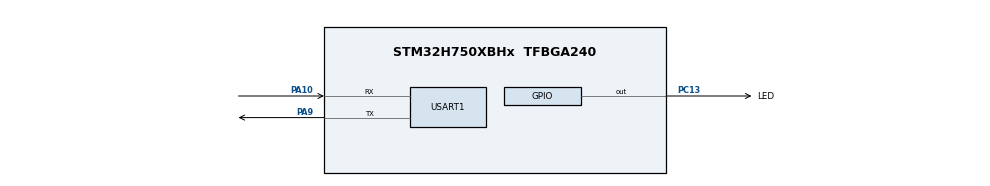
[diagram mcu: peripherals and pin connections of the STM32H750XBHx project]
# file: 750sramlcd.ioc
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CORTEX_M7.CPU_DCache=Enabled
CORTEX_M7.CPU_ICache=Enabled
CORTEX_M7.MPU_Control=__NULL
Mcu.Family=STM32H7
Mcu.Name=STM32H750XBHx
Mcu.Package=TFBGA240
NVIC.PriorityGroup=NVIC_PRIORITYGROUP_4
NVIC.USART1_IRQn=true\:0\:0\:false\:false\:true\:true\:true\:true
PA10.Mode=Asynchronous
PA10.Signal=USART1_RX
PA13\ (JTMS/SWDIO).Mode=Trace_Asynchronous_SW
PA13\ (JTMS/SWDIO).Signal=DEBUG_JTMS-SWDIO
PA14\ (JTCK/SWCLK).Mode=Trace_Asynchronous_SW
PA14\ (JTCK/SWCLK).Signal=DEBUG_JTCK-SWCLK
PA9.Mode=Asynchronous
PA9.Signal=USART1_TX
PB3\ (JTDO/TRACESWO).Mode=Trace_Asynchronous_SW
PB3\ (JTDO/TRACESWO).Signal=DEBUG_JTDO-SWO
PC13.GPIO_Label=LED
PC13.Signal=GPIO_Output
PH0-OSC_IN\ (PH0).Mode=HSE-External-Oscillator
PH0-OSC_IN\ (PH0).Signal=RCC_OSC_IN
PH1-OSC_OUT\ (PH1).Mode=HSE-External-Oscillator
PH1-OSC_OUT\ (PH1).Signal=RCC_OSC_OUT
ProjectManager.HeapSize=0x200
ProjectManager.StackSize=0x400
ProjectManager.TargetToolchain=STM32CubeIDE
RCC.ADCFreq_Value=50390625
RCC.APB1Freq_Value=120000000
RCC.APB2Freq_Value=120000000
RCC.APB3Freq_Value=120000000
RCC.APB4Freq_Value=120000000
RCC.CortexFreq_Value=480000000
RCC.D1PPRE=RCC_APB3_DIV2
RCC.D2PPRE1=RCC_APB1_DIV2
RCC.D2PPRE2=RCC_APB2_DIV2
RCC.D3PPRE=RCC_APB4_DIV2
RCC.DIVM1=5
RCC.DIVM3=5
RCC.DIVN1=192
RCC.DIVQ1=20
RCC.DIVR3=19
RCC.HCLKFreq_Value=240000000
RCC.HPRE=RCC_HCLK_DIV2
RCC.PLL2_VCI_Range-AdvancedSettings=RCC_PLL2VCIRANGE_0
RCC.PLL3FRACN=0
RCC.PLLSourceVirtual=RCC_PLLSOURCE_HSE
RCC.ProductRev=revV
RCC.SYSCLKFreq_VALUE=480000000
RCC.SYSCLKSource=RCC_SYSCLKSOURCE_PLLCLK
RCC.SupplySource=PWR_EXTERNAL_SOURCE_SUPPLY
RCC.USBFreq_Value=48000000
USART1.FIFOMode=FIFOMODE_DISABLE
USART1.Parity=PARITY_EVEN
USART1.VirtualMode-Asynchronous=VM_ASYNC
USART1.WordLength=WORDLENGTH_9B
board=custom

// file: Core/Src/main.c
/* USER CODE BEGIN Header */
/**
  ******************************************************************************
  * @file           : main.c
  * @brief          : Main program body
  ******************************************************************************
  * @attention
  *
  * Copyright (c) 2024 STMicroelectronics.
  * All rights reserved.
  *
  * This software is licensed under terms that can be found in the LICENSE file
  * in the root directory of this software component.
  * If no LICENSE file comes with this software, it is provided AS-IS.
  *
  ******************************************************************************
  */
/* USER CODE END Header */
#include "main.h"

/* USER CODE BEGIN Includes */
#include <stdio.h>

/* USER CODE END Includes */

UART_HandleTypeDef huart1;

void SystemClock_Config(void);
static void MX_GPIO_Init(void);
static void MX_USART1_UART_Init(void);

/* USER CODE BEGIN 0 */

uint8_t recbyte, sendbyte;

void myprintf(char *text){
	HAL_UART_Transmit(&huart1, text, strlen(text),10);
}

int _write(int file, char *ptr, int len)
{
	HAL_UART_Transmit(&huart1, ptr, len,10);
   return len;
}

void HAL_UART_TxCpltCallback(UART_HandleTypeDef *huart)
{
	HAL_GPIO_TogglePin(LED_GPIO_Port,LED_Pin);

}

void HAL_UART_RxCpltCallback(UART_HandleTypeDef *huart){
	sendbyte=recbyte;
	//if((sendbyte>=0x61)&&(sendbyte<=0x7a))sendbyte-=0x20;
	HAL_UART_Transmit(&huart1, &sendbyte,1,10);
	HAL_UART_Receive_IT(&huart1, &recbyte, 1);

	ms_proc_char(recbyte);
}

/* USER CODE END 0 */

int main(void)
{
  /* USER CODE BEGIN 1 */
  // Set stdout to be unbuffered
  //setvbuf(stdout, NULL, _IONBF, 0);

  /* USER CODE END 1 */

  /* Enable I-Cache---------------------------------------------------------*/
  SCB_EnableICache();

  /* Enable D-Cache---------------------------------------------------------*/
  SCB_EnableDCache();

  /* MCU Configuration--------------------------------------------------------*/

  /* Reset of all peripherals, Initializes the Flash interface and the Systick. */
  HAL_Init();

  /* Configure the system clock */
  SystemClock_Config();

  /* Initialize all configured peripherals */
  MX_GPIO_Init();
  MX_USART1_UART_Init();

  /* Infinite loop */
  /* USER CODE BEGIN WHILE */
  printf("Start\n");
  HAL_UART_Receive_IT(&huart1, &recbyte, 1);
  while (1)
  {
    /* USER CODE END WHILE */

    /* USER CODE BEGIN 3 */
	  HAL_GPIO_TogglePin(LED_GPIO_Port,LED_Pin);
	  HAL_Delay(250);
	  //myprintf(".");
  }
  /* USER CODE END 3 */
}

void SystemClock_Config(void)
{
  RCC_OscInitTypeDef RCC_OscInitStruct = {0};
  RCC_ClkInitTypeDef RCC_ClkInitStruct = {0};

  /** Supply configuration update enable
  */
  HAL_PWREx_ConfigSupply(PWR_EXTERNAL_SOURCE_SUPPLY);

  /** Configure the main internal regulator output voltage
  */
  __HAL_PWR_VOLTAGESCALING_CONFIG(PWR_REGULATOR_VOLTAGE_SCALE0);

  while(!__HAL_PWR_GET_FLAG(PWR_FLAG_VOSRDY)) {}

  /** Initializes the RCC Oscillators according to the specified parameters
  * in the RCC_OscInitTypeDef structure.
  */
  RCC_OscInitStruct.OscillatorType = RCC_OSCILLATORTYPE_HSE;
  RCC_OscInitStruct.HSEState = RCC_HSE_ON;
  RCC_OscInitStruct.PLL.PLLState = RCC_PLL_ON;
  RCC_OscInitStruct.PLL.PLLSource = RCC_PLLSOURCE_HSE;
  RCC_OscInitStruct.PLL.PLLM = 5;
  RCC_OscInitStruct.PLL.PLLN = 192;
  RCC_OscInitStruct.PLL.PLLP = 2;
  RCC_OscInitStruct.PLL.PLLQ = 20;
  RCC_OscInitStruct.PLL.PLLR = 2;
  RCC_OscInitStruct.PLL.PLLRGE = RCC_PLL1VCIRANGE_2;
  RCC_OscInitStruct.PLL.PLLVCOSEL = RCC_PLL1VCOWIDE;
  RCC_OscInitStruct.PLL.PLLFRACN = 0;
  if (HAL_RCC_OscConfig(&RCC_OscInitStruct) != HAL_OK)
  {
    Error_Handler();
  }

  /** Initializes the CPU, AHB and APB buses clocks
  */
  RCC_ClkInitStruct.ClockType = RCC_CLOCKTYPE_HCLK|RCC_CLOCKTYPE_SYSCLK
                              |RCC_CLOCKTYPE_PCLK1|RCC_CLOCKTYPE_PCLK2
                              |RCC_CLOCKTYPE_D3PCLK1|RCC_CLOCKTYPE_D1PCLK1;
  RCC_ClkInitStruct.SYSCLKSource = RCC_SYSCLKSOURCE_PLLCLK;
  RCC_ClkInitStruct.SYSCLKDivider = RCC_SYSCLK_DIV1;
  RCC_ClkInitStruct.AHBCLKDivider = RCC_HCLK_DIV2;
  RCC_ClkInitStruct.APB3CLKDivider = RCC_APB3_DIV2;
  RCC_ClkInitStruct.APB1CLKDivider = RCC_APB1_DIV2;
  RCC_ClkInitStruct.APB2CLKDivider = RCC_APB2_DIV2;
  RCC_ClkInitStruct.APB4CLKDivider = RCC_APB4_DIV2;

  if (HAL_RCC_ClockConfig(&RCC_ClkInitStruct, FLASH_LATENCY_4) != HAL_OK)
  {
    Error_Handler();
  }
}

static void MX_USART1_UART_Init(void)
{

  huart1.Instance = USART1;
  huart1.Init.BaudRate = 115200;
  huart1.Init.WordLength = UART_WORDLENGTH_9B;
  huart1.Init.StopBits = UART_STOPBITS_1;
  huart1.Init.Parity = UART_PARITY_EVEN;
  huart1.Init.Mode = UART_MODE_TX_RX;
  huart1.Init.HwFlowCtl = UART_HWCONTROL_NONE;
  huart1.Init.OverSampling = UART_OVERSAMPLING_16;
  huart1.Init.OneBitSampling = UART_ONE_BIT_SAMPLE_DISABLE;
  huart1.Init.ClockPrescaler = UART_PRESCALER_DIV1;
  huart1.AdvancedInit.AdvFeatureInit = UART_ADVFEATURE_NO_INIT;
  if (HAL_UART_Init(&huart1) != HAL_OK)
  {
    Error_Handler();
  }
  if (HAL_UARTEx_SetTxFifoThreshold(&huart1, UART_TXFIFO_THRESHOLD_1_8) != HAL_OK)
  {
    Error_Handler();
  }
  if (HAL_UARTEx_SetRxFifoThreshold(&huart1, UART_RXFIFO_THRESHOLD_1_8) != HAL_OK)
  {
    Error_Handler();
  }
  if (HAL_UARTEx_DisableFifoMode(&huart1) != HAL_OK)
  {
    Error_Handler();
  }

}

static void MX_GPIO_Init(void)
{
  GPIO_InitTypeDef GPIO_InitStruct = {0};

  /* GPIO Ports Clock Enable */
  __HAL_RCC_GPIOA_CLK_ENABLE();
  __HAL_RCC_GPIOB_CLK_ENABLE();
  __HAL_RCC_GPIOC_CLK_ENABLE();
  __HAL_RCC_GPIOH_CLK_ENABLE();

  /*Configure GPIO pin Output Level */
  HAL_GPIO_WritePin(LED_GPIO_Port, LED_Pin, GPIO_PIN_RESET);

  /*Configure GPIO pin : LED_Pin */
  GPIO_InitStruct.Pin = LED_Pin;
  GPIO_InitStruct.Mode = GPIO_MODE_OUTPUT_PP;
  GPIO_InitStruct.Pull = GPIO_NOPULL;
  GPIO_InitStruct.Speed = GPIO_SPEED_FREQ_LOW;
  HAL_GPIO_Init(LED_GPIO_Port, &GPIO_InitStruct);

}

void Error_Handler(void)
{
  __disable_irq();
  while (1)
  {
  }
}
